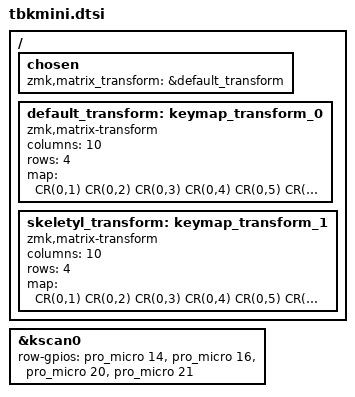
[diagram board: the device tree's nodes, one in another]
/*
 * Copyright (c) 2022 Casey Webster, Lau Kar Rui
 *
 * SPDX-License-Identifier: MIT
 */

#include "tbkmini_common.dtsi"

/ {
	chosen {
		zmk,matrix_transform = &default_transform;
	};

	default_transform: keymap_transform_0 {
		compatible = "zmk,matrix-transform";
        columns = <10>;
        rows = <4>;
// | SW2  | SW3  | SW4  | SW5  | SW6  |   | SW6  | SW5  | SW4  | SW3  | SW2  |
// | SW8  | SW9  | SW10 | SW11 | SW12 |   | SW12 | SW11 | SW10 | SW9  | SW8  |
// | SW14 | SW15 | SW16 | SW17 | SW18 |   | SW18 | SW17 | SW16 | SW15 | SW14 |
//                      | SW19 | SW20 | SW21 |   | SW21 | SW20 | SW19 |
        map = <
CR(0,1) CR(0,2) CR(0,3) CR(0,4) CR(0,5)  CR(0,6) CR(0,7) CR(0,8) CR(0,9) CR(0,10)
CR(1,1) CR(1,2) CR(1,3) CR(1,4) CR(1,5)  CR(1,6) CR(1,7) CR(1,8) CR(1,9) CR(1,10)
CR(2,1) CR(2,2) CR(2,3) CR(2,4) CR(2,5)  CR(2,6) CR(2,7) CR(2,8) CR(2,9) CR(2,10)
                        CR(3,3) CR(3,4) CR(3,5)  CR(3,6) CR(3,7) CR(3,8)
        >;
    };

// | k00  | k01  | k02  | k03  | k04  |                  | k45  | k44  | k43  | k42  | k41  |
// | k10  | k11  | k12  | k13  | k14  |                  | k55  | k54  | k53  | k52  | k51  |
// | k20  | k21  | k22  | k23  | k24  |                  | k65  | k64  | k63  | k62  | k61  |
//               | k32  | k33  | k34  |                  | k71  | k74  | k73  |
	skeletyl_transform: keymap_transform_1 {
		compatible = "zmk,matrix-transform";
		columns = <10>;
		rows = <4>;
		map = <
CR(0,1) CR(0,2) CR(0,3) CR(0,4) CR(0,5)                 CR(0,6) CR(0,7) CR(0,8) CR(0,9) CR(0,10)
CR(1,1) CR(1,2) CR(1,3) CR(1,4) CR(1,5)                 CR(1,6) CR(1,7) CR(1,8) CR(1,9) CR(1,10)
CR(2,1) CR(2,2) CR(2,3) CR(2,4) CR(2,5)                 CR(2,6) CR(2,7) CR(2,8) CR(2,9) CR(2,10)
                CR(3,3) CR(3,4) CR(3,1)                 CR(3,10) CR(3,7) CR(3,8)
		>;
	};
};


&kscan0 {
	row-gpios
		= <&pro_micro 14 (GPIO_ACTIVE_HIGH | GPIO_PULL_DOWN)>
		, <&pro_micro 16 (GPIO_ACTIVE_HIGH | GPIO_PULL_DOWN)>
		, <&pro_micro 20 (GPIO_ACTIVE_HIGH | GPIO_PULL_DOWN)>'
		, <&pro_micro 21 (GPIO_ACTIVE_HIGH | GPIO_PULL_DOWN)>
		;

};

// TODO: RGB node(s)
